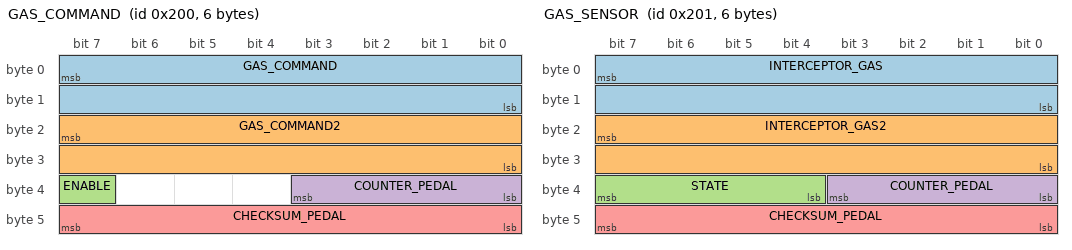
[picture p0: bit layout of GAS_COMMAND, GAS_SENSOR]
BO_ 512 GAS_COMMAND: 6 NEO
 SG_ GAS_COMMAND : 7|16@0+ (0.125677,-75.909) [0|1] "" INTERCEPTOR
 SG_ GAS_COMMAND2 : 23|16@0+ (0.251976,-76.601) [0|1] "" INTERCEPTOR
 SG_ ENABLE : 39|1@0+ (1,0) [0|1] "" INTERCEPTOR
 SG_ COUNTER_PEDAL : 35|4@0+ (1,0) [0|15] "" INTERCEPTOR
 SG_ CHECKSUM_PEDAL : 47|8@0+ (1,0) [0|255] "" INTERCEPTOR

BO_ 513 GAS_SENSOR: 6 INTERCEPTOR
 SG_ INTERCEPTOR_GAS : 7|16@0+ (0.125677,-75.909) [0|1] "" NEO
 SG_ INTERCEPTOR_GAS2 : 23|16@0+ (0.251976,-76.601) [0|1] "" NEO
 SG_ STATE : 39|4@0+ (1,0) [0|15] "" NEO
 SG_ COUNTER_PEDAL : 35|4@0+ (1,0) [0|15] "" NEO
 SG_ CHECKSUM_PEDAL : 47|8@0+ (1,0) [0|255] "" NEO

VAL_ 513 STATE 5 "FAULT_TIMEOUT" 4 "FAULT_STARTUP" 3 "FAULT_SCE" 2 "FAULT_SEND" 1 "FAULT_BAD_CHECKSUM" 0 "NO_FAULT" ;

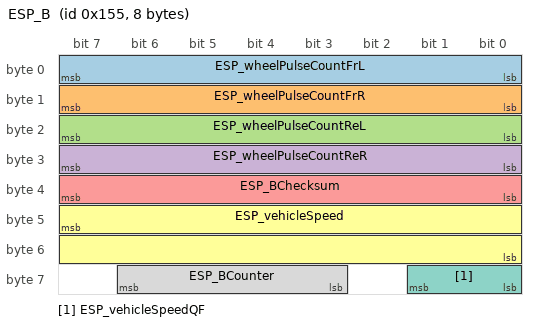
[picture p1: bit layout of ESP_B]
BO_ 341 ESP_B: 8 ESP
 SG_ ESP_wheelPulseCountFrL : 7|8@0+ (1,0) [0|254] "" NEO,EPAS
 SG_ ESP_wheelPulseCountFrR : 15|8@0+ (1,0) [0|254] "" NEO,EPAS
 SG_ ESP_wheelPulseCountReL : 23|8@0+ (1,0) [0|254] "" NEO,EPAS
 SG_ ESP_wheelPulseCountReR : 31|8@0+ (1,0) [0|254] "" NEO,EPAS
 SG_ ESP_BChecksum : 39|8@0+ (1,0) [0|255] "" NEO,EPAS
 SG_ ESP_vehicleSpeed : 47|16@0+ (0.01,0) [0|0] "kph" NEO,EPAS
 SG_ ESP_vehicleSpeedQF : 57|2@0+ (1,0) [1|2] "" NEO,EPAS
 SG_ ESP_BCounter : 62|4@0+ (1,0) [1|15] "" NEO,EPAS
